# MKM34ZA5 register map
Vendor: Freescale Semiconductor, Inc.; Series: Kinetis_M; File version: 1.6
CPU: CM0PLUS r0p0, little endian, no MPU, no FPU, VTOR, 2 interrupt priority bits
Registers are 8-bit, read-write, reset 0x0 unless marked. A register's access mark holds for its fields unless they carry their own. Offsets are from the block's base; [hi:lo] are bit positions; {n}, {i} and the like mark numbered series; 'fields as' and 'values as' point back to an identical list.

## DMA — DMA Controller
Base 0x40008000; register names take the prefix DMA_
{0x100+0x10*i} SAR{i} (i=0..3) 32-bit — Source Address Register
  [31:0] SAR
{0x104+0x10*i} DAR{i} (i=0..3) 32-bit — Destination Address Register
  [31:0] DAR
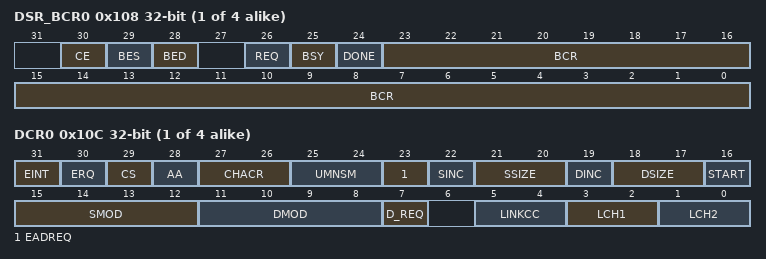
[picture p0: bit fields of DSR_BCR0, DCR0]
{0x108+0x10*i} DSR_BCR{i} (i=0..3) 32-bit — DMA Status Register / Byte Count Register
  [30] CE ro — Configuration Error
    0=No configuration error exists; 1=A configuration error has occurred
  [29] BES ro — Bus Error on Source
    0=No bus error occurred; 1=The DMA channel terminated with a bus error during the read portion of a transfer
  [28] BED ro — Bus Error on Destination
    0=No bus error occurred; 1=The DMA channel terminated with a bus error during the write portion of a transfer
  [26] REQ ro — Request
    0=No request is pending or the channel is currently active. Cleared when the channel is selected.; 1=The DMA channel has a transfer remaining and the channel is not selected
  [25] BSY ro — Busy
    0=DMA channel is inactive. Cleared when the DMA has finished the last transaction.; 1=BSY is set the first time the channel is enabled after a transfer is initiated
  [24] DONE — Transactions Done
    0=DMA transfer is not yet complete. Writing a 0 has no effect.; 1=DMA transfer completed. Writing a 1 to this bit clears all DMA status bits and should be used in an interrupt service routine to clear the DMA interrupt and error bits.
  [23:0] BCR
{0x10B+0x10*i} DSR{i} (i=0..3) — DMA_DSR{i} register.
{0x10C+0x10*i} DCR{i} (i=0..3) 32-bit — DMA Control Register
  [31] EINT — Enable Interrupt on Completion of Transfer
    0=No interrupt is generated; 1=Interrupt signal is enabled
  [30] ERQ — Enable Peripheral Request
    0=Peripheral request is ignored; 1=Enables peripheral request to initiate transfer. A software-initiated request (setting START) is always enabled.
  [29] CS — Cycle Steal
    0=DMA continuously makes read/write transfers until the BCR decrements to 0; 1=Forces a single read/write transfer per request
  [28] AA — Auto-align
    0=Auto-align disabled; 1=If SSIZE indicates a transfer no smaller than DSIZE, source accesses are auto-aligned; otherwise, destination accesses are auto-aligned. Source alignment takes precedence over destination alignment. If auto-alignment is enabled, the appropriate address register increments, regardless of DINC or SINC.
  [27:26] CHACR — Channel Access Control
  [25:24] UMNSM — User Mode, Nonsecure Mode
    0=Channel attributes are set to the current mode; 1=If the current mode is privileged and secure, then attributes are set to {privileged, secure}. Otherwise, writing this value terminates in an error.; 2=If the current mode is privileged and secure or if the current mode is user and secure, then attributes are set to {user, secure}. Otherwise, writing this value terminates in an error.; 3=If the current mode is privileged and secure, user and secure, or user and nonsecure, then attributes are set to {user, nonsecure}
  [23] EADREQ — Enable asynchronous DMA requests
    0=Disabled; 1=Enabled
  [22] SINC — Source Increment
    0=No change to SAR after a successful transfer; 1=The SAR increments by 1, 2, 4 as determined by the transfer size
  [21:20] SSIZE — Source Size
    0=32-bit; 1=8-bit; 2=16-bit
  [19] DINC — Destination Increment
    0=No change to the DAR after a successful transfer; 1=The DAR increments by 1, 2, 4 depending upon the size of the transfer
  [18:17] DSIZE — Destination Size
    0=32-bit; 1=8-bit; 2=16-bit
  [16] START wo — Start Transfer
    0=DMA inactive; 1=The DMA begins the transfer in accordance to the values in the TCDn. START is cleared automatically after one module clock and always reads as logic 0.
  [15:12] SMOD — Source Address Modulo
    0=Buffer disabled; 1=Circular buffer size is 16 bytes; 2=Circular buffer size is 32 bytes; 3=Circular buffer size is 64 bytes; 4=Circular buffer size is 128 bytes; 5=Circular buffer size is 256 bytes; 6=Circular buffer size is 512 bytes; 7=Circular buffer size is 1 KB; 8=Circular buffer size is 2 KB; 9=Circular buffer size is 4 KB; 10=Circular buffer size is 8 KB; 11=Circular buffer size is 16 KB; 12=Circular buffer size is 32 KB; 13=Circular buffer size is 64 KB; 14=Circular buffer size is 128 KB; 15=Circular buffer size is 256 KB
  [11:8] DMOD — Destination Address Modulo
    values as SMOD
  [7] D_REQ — Disable Request
    0=ERQ bit is not affected; 1=ERQ bit is cleared when the BCR is exhausted
  [5:4] LINKCC — Link Channel Control
    0=No channel-to-channel linking; 1=Perform a link to channel LCH1 after each cycle-steal transfer followed by a link to LCH2 after the BCR decrements to 0; 2=Perform a link to channel LCH1 after each cycle-steal transfer; 3=Perform a link to channel LCH1 after the BCR decrements to 0
  [3:2] LCH1 — Link Channel 1
    {v}=DMA Channel {v} (v=0..3)
  [1:0] LCH2 — Link Channel 2
    {v}=DMA Channel {v} (v=0..3)

## Notices in the file
Redistribution and use in source and binary forms, with or without modification,
are permitted provided that the following conditions are met:
o Redistributions of source code must retain the above copyright notice, this list
of conditions and the following disclaimer.
o Redistributions in binary form must reproduce the above copyright notice, this
list of conditions and the following disclaimer in the documentation and/or
other materials provided with the distribution.
o Neither the name of Freescale Semiconductor, Inc. nor the names of its
contributors may be used to endorse or promote products derived from this
software without specific prior written permission.
THIS SOFTWARE IS PROVIDED BY THE COPYRIGHT HOLDERS AND CONTRIBUTORS "AS IS" AND
ANY EXPRESS OR IMPLIED WARRANTIES, INCLUDING, BUT NOT LIMITED TO, THE IMPLIED
WARRANTIES OF MERCHANTABILITY AND FITNESS FOR A PARTICULAR PURPOSE ARE
DISCLAIMED. IN NO EVENT SHALL THE COPYRIGHT HOLDER OR CONTRIBUTORS BE LIABLE FOR
ANY DIRECT, INDIRECT, INCIDENTAL, SPECIAL, EXEMPLARY, OR CONSEQUENTIAL DAMAGES
(INCLUDING, BUT NOT LIMITED TO, PROCUREMENT OF SUBSTITUTE GOODS OR SERVICES;
LOSS OF USE, DATA, OR PROFITS; OR BUSINESS INTERRUPTION) HOWEVER CAUSED AND ON
ANY THEORY OF LIABILITY, WHETHER IN CONTRACT, STRICT LIABILITY, OR TORT
(INCLUDING NEGLIGENCE OR OTHERWISE) ARISING IN ANY WAY OUT OF THE USE OF THIS
SOFTWARE, EVEN IF ADVISED OF THE POSSIBILITY OF SUCH DAMAGE.
